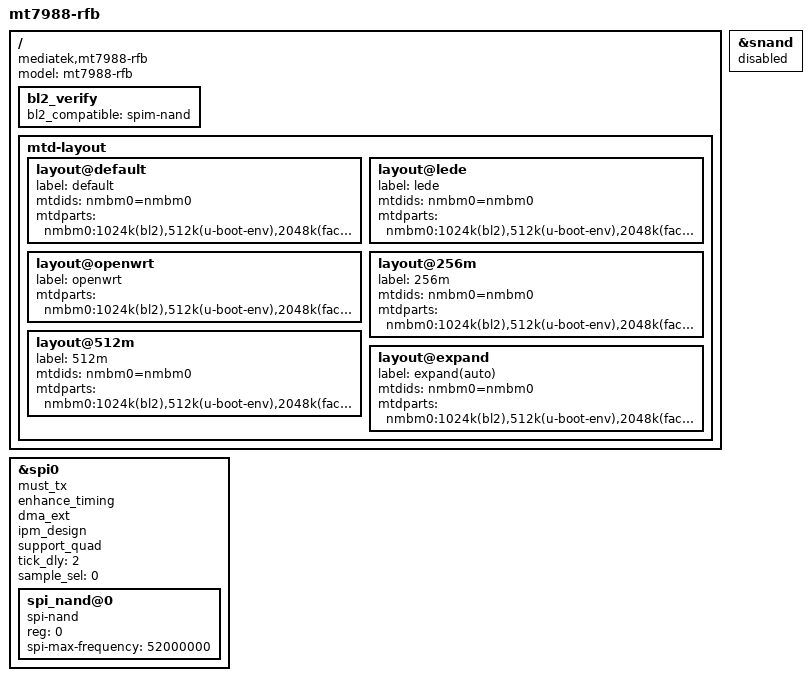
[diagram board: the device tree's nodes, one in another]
// SPDX-License-Identifier: GPL-2.0
/*
 * Copyright (c) 2022 MediaTek Inc.
 * Author: Sam Shih <sam.shih@mediatek.com>
 */

/dts-v1/;
#include "mt7988-10g-p1-rfb.dts"
#include <dt-bindings/gpio/gpio.h>

/ {
	model = "mt7988-rfb";
	compatible = "mediatek,mt7988-rfb", "mediatek,mt7988-spim-nand-rfb";

	bl2_verify {
		bl2_compatible = "spim-nand";
	};

	mtd-layout {
		layout@default {
			label = "default";
			mtdids = "nmbm0=nmbm0";
			mtdparts = "nmbm0:1024k(bl2),512k(u-boot-env),2048k(factory),2048k(fip),-(ubi)";
		};
		layout@lede {
			label = "lede";
			mtdids = "nmbm0=nmbm0";
			mtdparts = "nmbm0:1024k(bl2),512k(u-boot-env),2048k(factory),2048k(fip),-(ubi)";
		};
		layout@openwrt {
			label = "openwrt";
			mtdparts = "nmbm0:1024k(bl2),512k(u-boot-env),2048k(factory),2048k(fip),-(ubi)";
		};
		layout@256m {
			label = "256m";
			mtdids = "nmbm0=nmbm0";
			mtdparts = "nmbm0:1024k(bl2),512k(u-boot-env),2048k(factory),2048k(fip),238592k(ubi)";
		};
		layout@512m {
			label = "512m";
			mtdids = "nmbm0=nmbm0";
			mtdparts = "nmbm0:1024k(bl2),512k(u-boot-env),2048k(factory),2048k(fip),484352k(ubi)";
		};
		layout@expand {
			label = "expand(auto)";
			mtdids = "nmbm0=nmbm0";
			mtdparts = "nmbm0:1024k(bl2),512k(u-boot-env),2048k(factory),2048k(fip),-(ubi)";
		};
	};
};

&snand {
	status = "disabled";
};

&spi0 {
	#address-cells = <1>;
	#size-cells = <0>;
	status = "okay";
	must_tx;
	enhance_timing;
	dma_ext;
	ipm_design;
	support_quad;
	tick_dly = <2>;
	sample_sel = <0>;

	spi_nand@0 {
		compatible = "spi-nand";
		reg = <0>;
		spi-max-frequency = <52000000>;
	};
};


